AUTOSAR XML (schema 00045)
package /EvAdc
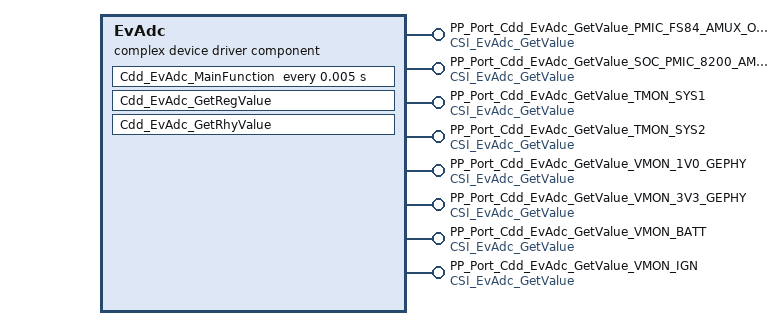
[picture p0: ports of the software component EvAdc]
  complex device driver sw component type EvAdc
    8 x provide port, all with provided-interface=CSI_EvAdc_GetValue:
      PP_Port_Cdd_EvAdc_GetValue_PMIC_FS84_AMUX_OUT
      PP_Port_Cdd_EvAdc_GetValue_SOC_PMIC_8200_AMUX_OUT
      PP_Port_Cdd_EvAdc_GetValue_TMON_SYS1
      PP_Port_Cdd_EvAdc_GetValue_TMON_SYS2
      PP_Port_Cdd_EvAdc_GetValue_VMON_1V0_GEPHY
      PP_Port_Cdd_EvAdc_GetValue_VMON_3V3_GEPHY
      PP_Port_Cdd_EvAdc_GetValue_VMON_BATT
      PP_Port_Cdd_EvAdc_GetValue_VMON_IGN
    behavior Cdd_EvAdc_IB: handle-termination-and-restart=NO-SUPPORT
      timing event Event_5ms_Cdd_EvAdc_MainFunction: start-on-event=Cdd_EvAdc_MainFunction, period=0.005
      16 x operation invoked event:
        oie_PP_Port_Cdd_EvAdc_GetRegValue_J3_PMIC_8200_AMUX_OUT_GetRegValue: start-on-event=Cdd_EvAdc_GetRegValue, operation=PP_Port_Cdd_EvAdc_GetValue_SOC_PMIC_8200_AMUX_OUT.GetRegValue
        oie_PP_Port_Cdd_EvAdc_GetRegValue_PMIC_FS84_AMUX_OUT_GetRegValue: start-on-event=Cdd_EvAdc_GetRegValue, operation=PP_Port_Cdd_EvAdc_GetValue_PMIC_FS84_AMUX_OUT.GetRegValue
        oie_PP_Port_Cdd_EvAdc_GetRegValue_TMON_SYS1_GetRegValue: start-on-event=Cdd_EvAdc_GetRegValue, operation=PP_Port_Cdd_EvAdc_GetValue_TMON_SYS1.GetRegValue
        oie_PP_Port_Cdd_EvAdc_GetRegValue_TMON_SYS2_GetRegValue: start-on-event=Cdd_EvAdc_GetRegValue, operation=PP_Port_Cdd_EvAdc_GetValue_TMON_SYS2.GetRegValue
        oie_PP_Port_Cdd_EvAdc_GetRegValue_VMON_1V0_GEPHY_GetRegValue: start-on-event=Cdd_EvAdc_GetRegValue, operation=PP_Port_Cdd_EvAdc_GetValue_VMON_1V0_GEPHY.GetRegValue
        oie_PP_Port_Cdd_EvAdc_GetRegValue_VMON_3V3_GEPHY_GetRegValue: start-on-event=Cdd_EvAdc_GetRegValue, operation=PP_Port_Cdd_EvAdc_GetValue_VMON_3V3_GEPHY.GetRegValue
        oie_PP_Port_Cdd_EvAdc_GetRegValue_VMON_BATT_GetRegValue: start-on-event=Cdd_EvAdc_GetRegValue, operation=PP_Port_Cdd_EvAdc_GetValue_VMON_BATT.GetRegValue
        oie_PP_Port_Cdd_EvAdc_GetRegValue_VMON_IGN_GetRegValue: start-on-event=Cdd_EvAdc_GetRegValue, operation=PP_Port_Cdd_EvAdc_GetValue_VMON_IGN.GetRegValue
        oie_PP_Port_Cdd_EvAdc_GetValue_PMIC_FS84_AMUX_OUT_GetPhyValue: start-on-event=Cdd_EvAdc_GetRhyValue, operation=PP_Port_Cdd_EvAdc_GetValue_PMIC_FS84_AMUX_OUT.GetPhyValue
        oie_PP_Port_Cdd_EvAdc_GetValue_SOC_PMIC_8200_AMUX_OUT_GetPhyValue: start-on-event=Cdd_EvAdc_GetRhyValue, operation=PP_Port_Cdd_EvAdc_GetValue_SOC_PMIC_8200_AMUX_OUT.GetPhyValue
        oie_PP_Port_Cdd_EvAdc_GetValue_TMON_SYS1_GetPhyValue: start-on-event=Cdd_EvAdc_GetRhyValue, operation=PP_Port_Cdd_EvAdc_GetValue_TMON_SYS1.GetPhyValue
        oie_PP_Port_Cdd_EvAdc_GetValue_TMON_SYS2_GetPhyValue: start-on-event=Cdd_EvAdc_GetRhyValue, operation=PP_Port_Cdd_EvAdc_GetValue_TMON_SYS2.GetPhyValue
        oie_PP_Port_Cdd_EvAdc_GetValue_VMON_1V0_GEPHY_GetPhyValue: start-on-event=Cdd_EvAdc_GetRhyValue, operation=PP_Port_Cdd_EvAdc_GetValue_VMON_1V0_GEPHY.GetPhyValue
        oie_PP_Port_Cdd_EvAdc_GetValue_VMON_3V3_GEPHY_GetPhyValue: start-on-event=Cdd_EvAdc_GetRhyValue, operation=PP_Port_Cdd_EvAdc_GetValue_VMON_3V3_GEPHY.GetPhyValue
        oie_PP_Port_Cdd_EvAdc_GetValue_VMON_BATT_GetPhyValue: start-on-event=Cdd_EvAdc_GetRhyValue, operation=PP_Port_Cdd_EvAdc_GetValue_VMON_BATT.GetPhyValue
        oie_PP_Port_Cdd_EvAdc_GetValue_VMON_IGN_GetPhyValue: start-on-event=Cdd_EvAdc_GetRhyValue, operation=PP_Port_Cdd_EvAdc_GetValue_VMON_IGN.GetPhyValue
      port-api-options:
        {enable-take-address=false, error-handling=NO-TRANSFORMER-ERROR-HANDLING, indirect-api=false, port-defined-argument-value{value=channel:0, value-type=uint8_t}, port=PP_Port_Cdd_EvAdc_GetValue_VMON_BATT}
        {enable-take-address=false, error-handling=NO-TRANSFORMER-ERROR-HANDLING, indirect-api=false, port-defined-argument-value{value=channel:1, value-type=uint8_t}, port=PP_Port_Cdd_EvAdc_GetValue_VMON_IGN}
        {enable-take-address=false, error-handling=NO-TRANSFORMER-ERROR-HANDLING, indirect-api=false, port-defined-argument-value{value=channel:2, value-type=uint8_t}, port=PP_Port_Cdd_EvAdc_GetValue_SOC_PMIC_8200_AMUX_OUT}
        {enable-take-address=false, error-handling=NO-TRANSFORMER-ERROR-HANDLING, indirect-api=false, port-defined-argument-value{value=channel:3, value-type=uint8_t}, port=PP_Port_Cdd_EvAdc_GetValue_PMIC_FS84_AMUX_OUT}
        {enable-take-address=false, error-handling=NO-TRANSFORMER-ERROR-HANDLING, indirect-api=false, port-defined-argument-value{value=channel:4, value-type=uint8_t}, port=PP_Port_Cdd_EvAdc_GetValue_VMON_1V0_GEPHY}
        {enable-take-address=false, error-handling=NO-TRANSFORMER-ERROR-HANDLING, indirect-api=false, port-defined-argument-value{value=channel:5, value-type=uint8_t}, port=PP_Port_Cdd_EvAdc_GetValue_VMON_3V3_GEPHY}
        {enable-take-address=false, error-handling=NO-TRANSFORMER-ERROR-HANDLING, indirect-api=false, port-defined-argument-value{value=channel:6, value-type=uint8_t}, port=PP_Port_Cdd_EvAdc_GetValue_TMON_SYS1}
        {enable-take-address=false, error-handling=NO-TRANSFORMER-ERROR-HANDLING, indirect-api=false, port-defined-argument-value{value=channel:7, value-type=uint8_t}, port=PP_Port_Cdd_EvAdc_GetValue_TMON_SYS2}
      runnable Cdd_EvAdc_GetRegValue
      runnable Cdd_EvAdc_GetRhyValue
      runnable Cdd_EvAdc_MainFunction
  swc implementation EvAdcImpl: programming-language=C, sw-version=1.0.0, vendor-id=0, behavior=Cdd_EvAdc_IB
    code-descriptors:
      code Code_Descriptor: artifact-descriptors=[{short-label=SWHDR, category=SWHDR}, {short-label=SWSRC, category=SWSRC}]
    resource consumption EvAdc_Resource
      memory section CODE: sw-addrmethod=CODE
      memory section VAR_UNSPECIFIED: sw-addrmethod=VAR
